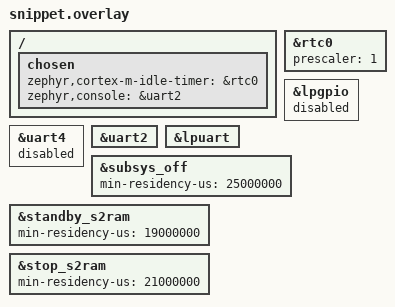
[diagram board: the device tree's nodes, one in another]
/* Copyright (C) 2025 Alif Semiconductor - All Rights Reserved.
 * Use, distribution and modification of this code is permitted under the
 * terms stated in the Alif Semiconductor Software License Agreement
 *
 * You should have received a copy of the Alif Semiconductor Software
 * License Agreement with this file. If not, please write to:
 * contact@alifsemi.com, or visit: https://alifsemi.com/license
 *
 */

&rtc0 {
	prescaler = <1>;
	status = "okay";
};

&lpgpio {
	status = "disabled";
};

&uart4 {
	status = "disabled";
};

&uart2 {
	status = "okay";
};

&lpuart {
	status = "okay";
};

&subsys_off {
	min-residency-us = <25000000>;
	status = "okay";
};

&standby_s2ram {
	min-residency-us = <19000000>;
	status = "okay";
};

&stop_s2ram {
	min-residency-us = <21000000>;
	status = "okay";
};

/ {
	chosen {
		zephyr,cortex-m-idle-timer = &rtc0;
		zephyr,console = &uart2;
	};
};
